# SAM9X75D5MN0 register map
Vendor: Microchip Technology; Series: SAM9X7; File version: 0
Registers are 32-bit, read-write, reset 0x0 unless marked. A register's access mark holds for its fields unless they carry their own. Offsets are from the block's base; [hi:lo] are bit positions; {n}, {i} and the like mark numbered series; <NAME> marks a mode.

## PIOA — Parallel Input/Output Controller
Base 0xFFFFF400; register names take the prefix PIO_
Same registers: PIOB 0xFFFFF600, PIOC 0xFFFFF800, PIOD 0xFFFFFA00
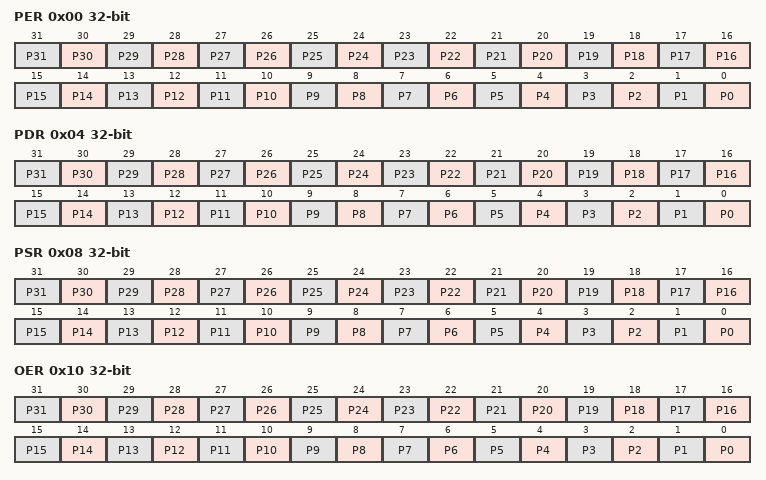
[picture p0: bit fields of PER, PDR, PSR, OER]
0x00 PER wo — PIO Enable Register
  [all] fields
    0=No effect; 1=Enables the PIO to control the corresponding pin (disables peripheral control of the pin)
  [n] P{n} (n=0..31) — PIO Enable
0x04 PDR wo — PIO Disable Register
  [all] fields
    0=No effect; 1=Disables the PIO from controlling the corresponding pin (enables peripheral control of the pin)
  [n] P{n} (n=0..31) — PIO Disable
0x08 PSR ro — PIO Status Register
  [all] fields
    0=PIO is inactive on the corresponding I/O line (peripheral is active); 1=PIO is active on the corresponding I/O line (peripheral is inactive)
  [n] P{n} (n=0..31) — PIO Status
0x10 OER wo — Output Enable Register
  [all] fields
    0=No effect; 1=Enables the output on the I/O line
  [n] P{n} (n=0..31) — Output Enable
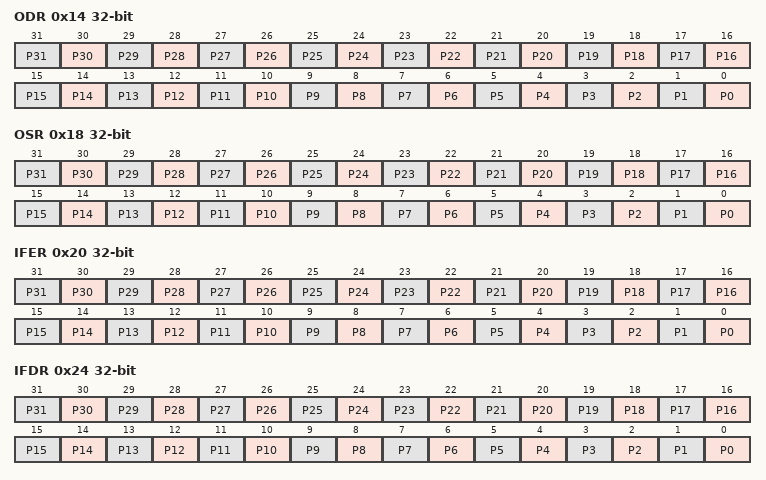
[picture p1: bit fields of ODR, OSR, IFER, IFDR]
0x14 ODR wo — Output Disable Register
  [all] fields
    0=No effect; 1=Disables the output on the I/O line
  [n] P{n} (n=0..31) — Output Disable
0x18 OSR ro — Output Status Register
  [all] fields
    0=The I/O line is a pure input; 1=The I/O line is enabled in output
  [n] P{n} (n=0..31) — Output Status
0x20 IFER wo — Glitch Input Filter Enable Register
  [all] fields
    0=No effect; 1=Enables the input glitch filter on the I/O line
  [n] P{n} (n=0..31) — Input Filter Enable
0x24 IFDR wo — Glitch Input Filter Disable Register
  [all] fields
    0=No effect; 1=Disables the input glitch filter on the I/O line
  [n] P{n} (n=0..31) — Input Filter Disable
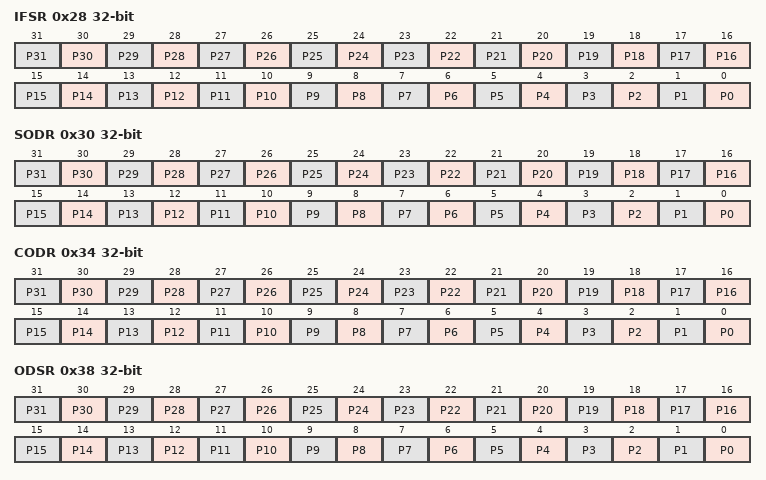
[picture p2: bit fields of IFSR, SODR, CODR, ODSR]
0x28 IFSR ro — Glitch Input Filter Status Register
  [all] fields
    0=The input glitch filter is disabled on the I/O line; 1=The input glitch filter is enabled on the I/O line
  [n] P{n} (n=0..31) — Input Filter Status
0x30 SODR wo — Set Output Data Register
  [all] fields
    0=No effect; 1=Sets the data to be driven on the I/O line
  [n] P{n} (n=0..31) — Set Output Data
0x34 CODR wo — Clear Output Data Register
  [all] fields
    0=No effect; 1=Clears the data to be driven on the I/O line
  [n] P{n} (n=0..31) — Clear Output Data
0x38 ODSR — Output Data Status Register
  [all] fields
    0=The data to be driven on the I/O line is 0; 1=The data to be driven on the I/O line is 1
  [n] P{n} (n=0..31) — Output Data Status
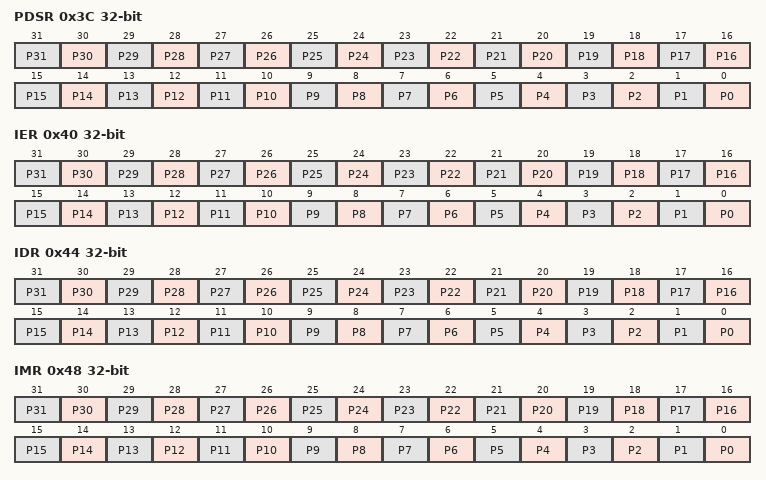
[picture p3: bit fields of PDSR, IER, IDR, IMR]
0x3C PDSR ro — Pin Data Status Register
  [all] fields
    0=The I/O line is at level 0; 1=The I/O line is at level 1
  [n] P{n} (n=0..31) — Output Data Status
0x40 IER wo — Interrupt Enable Register
  [all] fields
    0=No effect; 1=Enables the input change interrupt on the I/O line
  [n] P{n} (n=0..31) — Input Change Interrupt Enable
0x44 IDR wo — Interrupt Disable Register
  [all] fields
    0=No effect; 1=Disables the input change interrupt on the I/O line
  [n] P{n} (n=0..31) — Input Change Interrupt Disable
0x48 IMR ro — Interrupt Mask Register
  [all] fields
    0=Input change interrupt is disabled on the I/O line; 1=Input change interrupt is enabled on the I/O line
  [n] P{n} (n=0..31) — Input Change Interrupt Mask
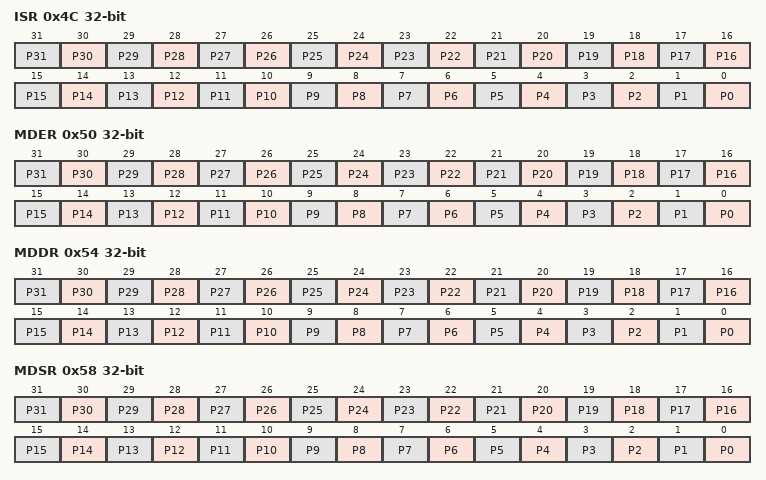
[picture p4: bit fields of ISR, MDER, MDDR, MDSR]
0x4C ISR ro — Interrupt Status Register
  [all] fields
    0=No input change has been detected on the I/O line since PIO_ISR was last read or since reset; 1=At least one input change has been detected on the I/O line since PIO_ISR was last read or since reset
  [n] P{n} (n=0..31) — Input Change Interrupt Status
0x50 MDER wo — Multi-driver Enable Register
  [all] fields
    0=No effect; 1=Enables multi-drive on the I/O line
  [n] P{n} (n=0..31) — Multi-drive Enable
0x54 MDDR wo — Multi-driver Disable Register
  [all] fields
    0=No effect; 1=Disables multi-drive on the I/O line
  [n] P{n} (n=0..31) — Multi-drive Disable
0x58 MDSR ro — Multi-driver Status Register
  [all] fields
    0=The multi-drive is disabled on the I/O line. The pin is driven at high- and low-level.; 1=The multi-drive is enabled on the I/O line. The pin is driven at low-level only.
  [n] P{n} (n=0..31) — Multi-drive Status
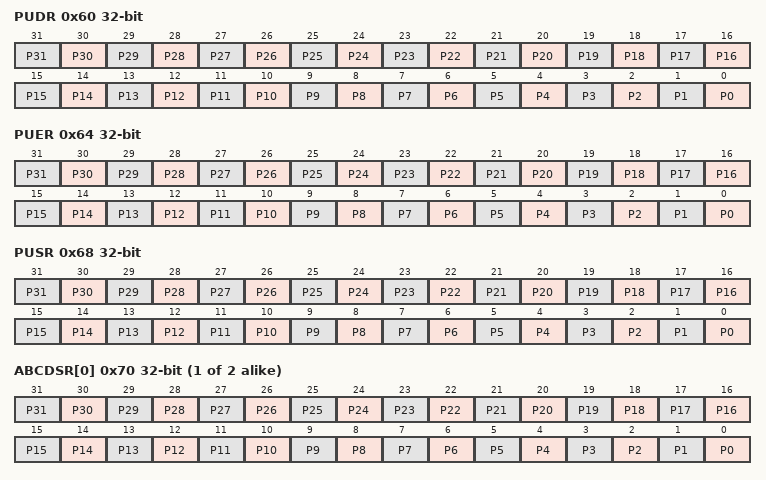
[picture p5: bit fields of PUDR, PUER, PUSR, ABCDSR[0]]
0x60 PUDR wo — Pull-Up Disable Register
  [all] fields
    0=No effect; 1=Disables the pullup resistor on the I/O line
  [n] P{n} (n=0..31) — Pull-Up Disable
0x64 PUER wo — Pull-Up Enable Register
  [all] fields
    0=No effect; 1=Enables the pullup resistor on the I/O line
  [n] P{n} (n=0..31) — Pull-Up Enable
0x68 PUSR ro — Pad Pull-Up Status Register
  [all] fields
    0=Pullup resistor is enabled on the I/O line; 1=Pullup resistor is disabled on the I/O line
  [n] P{n} (n=0..31) — Pull-Up Status
{0x70+4i} ABCDSR[{i}] (i=0..1) — Peripheral ABCD Select Register 1
  [all] fields
    0=Assigns the I/O line to the Peripheral A or C function; 1=Assigns the I/O line to the Peripheral B or D function
  [n] P{n} (n=0..31) — Peripheral Select
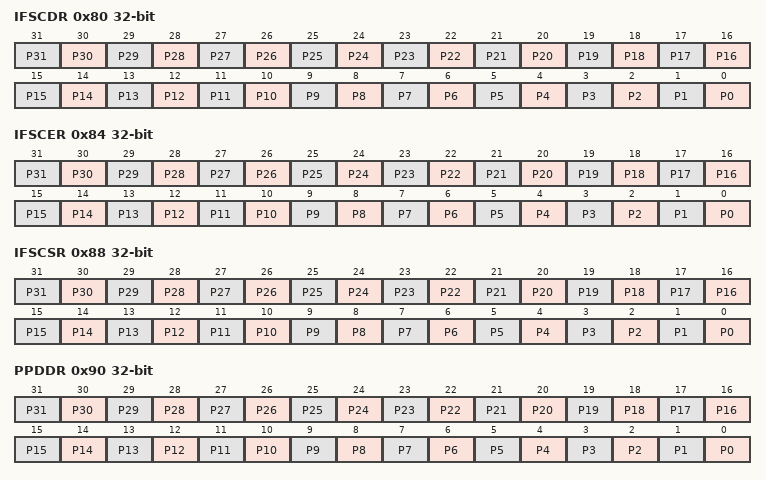
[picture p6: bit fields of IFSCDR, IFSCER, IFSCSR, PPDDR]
0x80 IFSCDR wo — Input Filter Slow Clock Disable Register
  [all] fields
    0=No effect; 1=The glitch filter is able to filter glitches with a duration < tperipheral clock/2
  [n] P{n} (n=0..31) — Peripheral Clock Glitch Filtering Select
0x84 IFSCER wo — Input Filter Slow Clock Enable Register
  [all] fields
    0=No effect; 1=The debouncing filter is able to filter pulses with a duration < tdiv_slck/2
  [n] P{n} (n=0..31) — Slow Clock Debouncing Filtering Select
0x88 IFSCSR ro — Input Filter Slow Clock Status Register
  [all] fields
    0=The glitch filter is able to filter glitches with a duration < tperipheral clock/2; 1=The debouncing filter is able to filter pulses with a duration < tdiv_slck/2
  [n] P{n} (n=0..31) — Glitch or Debouncing Filter Selection Status
0x8C SCDR — Slow Clock Divider Debouncing Register
  [13:0] DIV — Slow Clock Divider Selection for Debouncing
0x90 PPDDR wo — Pad Pull-Down Disable Register
  [all] fields
    0=No effect; 1=Disables the pulldown resistor on the I/O line
  [n] P{n} (n=0..31) — Pull-Down Disable
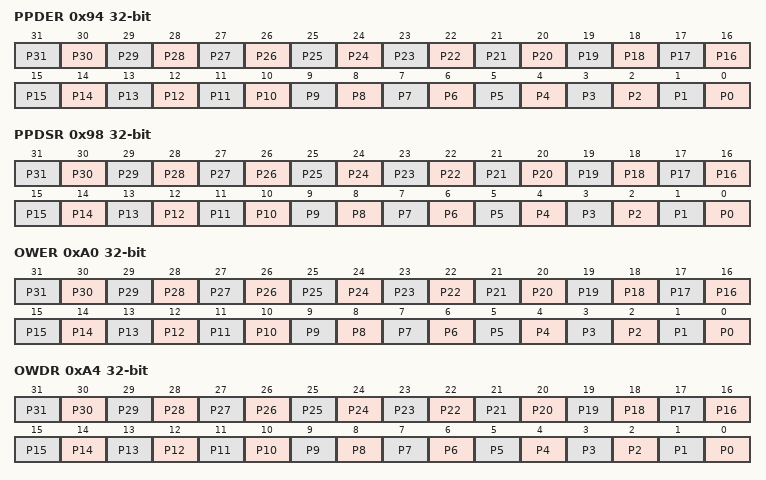
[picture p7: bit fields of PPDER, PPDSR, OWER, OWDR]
0x94 PPDER wo — Pad Pull-Down Enable Register
  [all] fields
    0=No effect; 1=Enables the pulldown resistor on the I/O line
  [n] P{n} (n=0..31) — Pull-Down Enable
0x98 PPDSR ro — Pad Pull-Down Status Register
  [all] fields
    0=Pulldown resistor is enabled on the I/O line; 1=Pulldown resistor is disabled on the I/O line
  [n] P{n} (n=0..31) — Pull-Down Status
0xA0 OWER wo — Output Write Enable
  [all] fields
    0=No effect; 1=Enables writing PIO_ODSR for the I/O line
  [n] P{n} (n=0..31) — Output Write Enable
0xA4 OWDR wo — Output Write Disable
  [all] fields
    0=No effect; 1=Disables writing PIO_ODSR for the I/O line
  [n] P{n} (n=0..31) — Output Write Disable
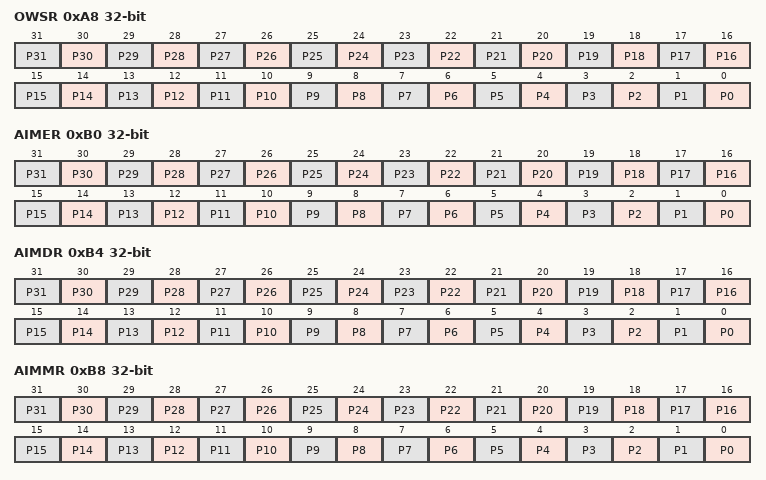
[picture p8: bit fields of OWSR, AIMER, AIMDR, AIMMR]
0xA8 OWSR ro — Output Write Status Register
  [all] fields
    0=Writing PIO_ODSR does not affect the I/O line; 1=Writing PIO_ODSR affects the I/O line
  [n] P{n} (n=0..31) — Output Write Status
0xB0 AIMER wo — Additional Interrupt Modes Enable Register
  [all] fields
    0=No effect; 1=The interrupt source is the event described in PIO_ELSR and PIO_FRLHSR
  [n] P{n} (n=0..31) — Additional Interrupt Modes Enable
0xB4 AIMDR wo — Additional Interrupt Modes Disable Register
  [all] fields
    0=No effect; 1=The Interrupt mode is set to the default Interrupt mode (Both-edge Detection)
  [n] P{n} (n=0..31) — Additional Interrupt Modes Disable
0xB8 AIMMR ro — Additional Interrupt Modes Mask Register
  [all] fields
    0=The interrupt source is a both-edge detection event; 1=The interrupt source is described by the registers PIO_ELSR and PIO_FRLHSR
  [n] P{n} (n=0..31) — IO Line Index
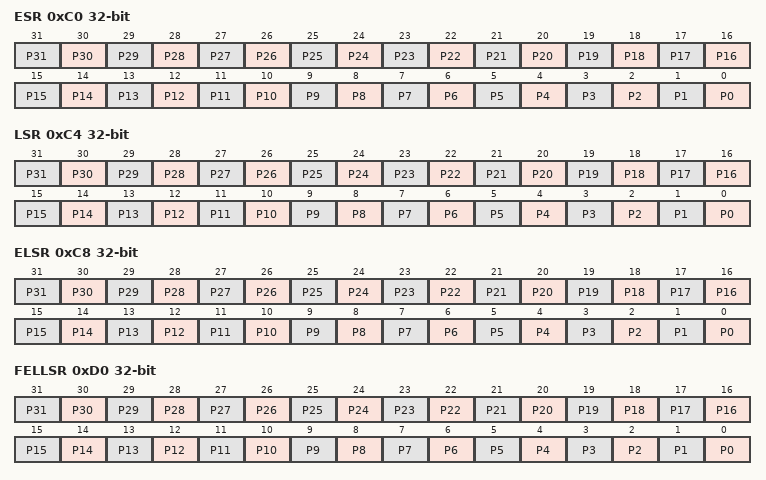
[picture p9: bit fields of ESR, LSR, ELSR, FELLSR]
0xC0 ESR wo — Edge Select Register
  [all] fields
    0=No effect; 1=The interrupt source is an edge-detection event
  [n] P{n} (n=0..31) — Edge Interrupt Selection
0xC4 LSR wo — Level Select Register
  [all] fields
    0=No effect; 1=The interrupt source is a level-detection event
  [n] P{n} (n=0..31) — Level Interrupt Selection
0xC8 ELSR ro — Edge/Level Status Register
  [all] fields
    0=The interrupt source is an edge-detection event; 1=The interrupt source is a level-detection event
  [n] P{n} (n=0..31) — Edge/Level Interrupt Source Selection
0xD0 FELLSR wo — Falling Edge/Low-Level Select Register
  [all] fields
    0=No effect; 1=The interrupt source is set to a falling edge detection or low-level detection event, depending on PIO_ELSR
  [n] P{n} (n=0..31) — Falling Edge/Low-Level Interrupt Selection
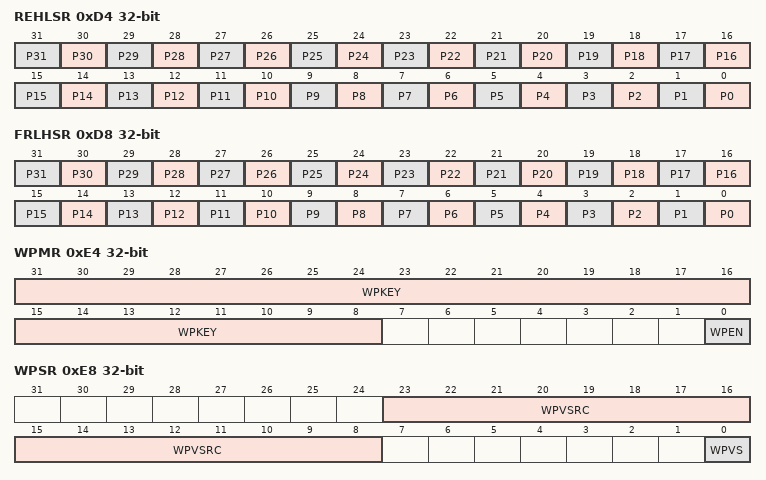
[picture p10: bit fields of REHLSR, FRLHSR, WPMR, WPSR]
0xD4 REHLSR wo — Rising Edge/High-Level Select Register
  [all] fields
    0=No effect; 1=The interrupt source is set to a rising edge detection or high-level detection event, depending on PIO_ELSR
  [n] P{n} (n=0..31) — Rising Edge/High-Level Interrupt Selection
0xD8 FRLHSR ro — Fall/Rise - Low/High Status Register
  [all] fields
    0=The interrupt source is a falling edge detection (if PIO_ELSR = 0) or low-level detection event (if PIO_ELSR = 1); 1=The interrupt source is a rising edge detection (if PIO_ELSR = 0) or high-level detection event (if PIO_ELSR = 1)
  [n] P{n} (n=0..31) — Edge/Level Interrupt Source Selection
0xE4 WPMR — Write Protection Mode Register
  [31:8] WPKEY — Write Protection Key
    0x50494F=PASSWD (Writing any other value in this field aborts the write operation of the WPEN bit. Always reads as 0.)
  [0] WPEN — Write Protection Enable
    0=Disables the write protection if WPKEY corresponds to 0x50494F ('PIO' in ASCII); 1=Enables the write protection if WPKEY corresponds to 0x50494F ('PIO' in ASCII)
0xE8 WPSR ro — Write Protection Status Register
  [23:8] WPVSRC — Write Protection Violation Source
  [0] WPVS — Write Protection Violation Status
    0=No write protection violation has occurred since the last read of the PIO_WPSR; 1=A write protection violation has occurred since the last read of the PIO_WPSR. If this violation is an unauthorized attempt to write a protected register, the associated violation is reported into field WPVSRC.
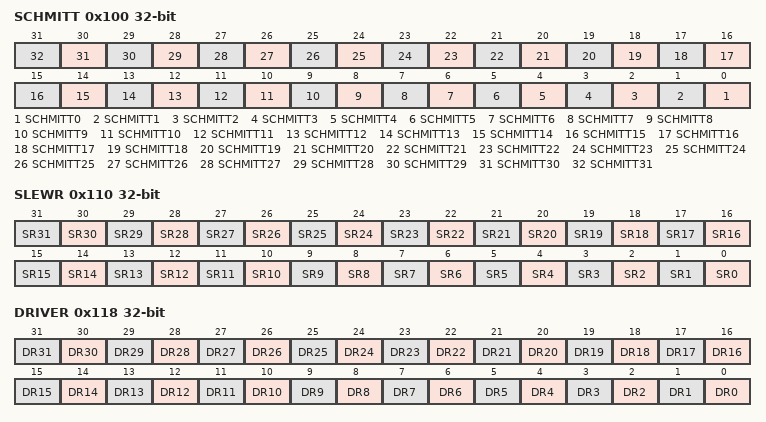
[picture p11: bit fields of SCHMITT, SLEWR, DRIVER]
0x100 SCHMITT — Schmitt Trigger Register
  [all] fields
    0=Schmitt trigger is enabled; 1=Schmitt trigger is disabled
  [n] SCHMITT{n} (n=0..31) — Schmitt Trigger Control
0x110 SLEWR — I/O Slewrate Control Register
  [all] fields
    0=DISABLED (No slewrate control.); 1=ENABLED (Slewrate controlled.)
  [n] SR{n} (n=0..31) — Slewrate Control for IO line {n}
0x118 DRIVER — I/O Drive Register
  [all] fields
    0=LOW (Lowest drive); 1=HIGH (Highest drive)
  [n] DR{n} (n=0..31) — Drive of I/O Line {n}
